AUTOSAR XML (schema 4-3-0)
package /MICROSAR/ComM_swc
  mode declaration group ComMMode: initial-mode=COMM_NO_COMMUNICATION
    mode COMM_NO_COMMUNICATION
    mode COMM_SILENT_COMMUNICATION
    mode COMM_FULL_COMMUNICATION
  data type mapping set ComMMode_DataTypeMappingSet: mode-request-type-map{implementation-data-type=ComM_ModeType, mode-group=ComMMode}  # Data Mapping for the Mode Declaration Group ComMMode.
package /MICROSAR/ComM_swc/DataTypes
  4 x impl type, all with category=TYPE_REFERENCE, implementation-data-type=uint8:
    ComM_ModeType: compu {0=COMM_NO_COMMUNICATION, 1=COMM_SILENT_COMMUNICATION, 2=COMM_FULL_COMMUNICATION}
    ComM_InhibitionStatusType: range raw 0..255
    ComM_UserHandleType: range raw 0..255
    NetworkHandleType: range raw 0..255, type-emitter=ComM
package /MICROSAR/ComM_swc/Interfaces
  4 x client server interface, all with is-service=true, service-kind=COM-MANAGER:
    ComM_UserRequest
      4 x operation:
        RequestComMode: possible-error=[ComM_UserRequest/E_NOT_OK, E_MODE_LIMITATION]
          arg ComMode: type=ComM_ModeType, direction=IN
        GetCurrentComMode: possible-error=ComM_UserRequest/E_NOT_OK
          arg ComMode: type=ComM_ModeType, direction=OUT
        GetMaxComMode: possible-error=ComM_UserRequest/E_NOT_OK
          arg ComMode: type=ComM_ModeType, direction=OUT
        GetRequestedComMode: possible-error=ComM_UserRequest/E_NOT_OK
          arg ComMode: type=ComM_ModeType, direction=OUT
      error E_NOT_OK: error-code=1
      error E_MODE_LIMITATION: error-code=2
    ComM_ECUModeLimitation
      4 x operation, all with possible-error=ComM_ECUModeLimitation/E_NOT_OK:
        LimitECUToNoComMode
          arg Status: type=boolean, direction=IN
        ReadInhibitCounter
          arg CounterValue: type=uint16, direction=OUT
        ResetInhibitCounter
        SetECUGroupClassification
          arg Status: type=ComM_InhibitionStatusType, direction=IN
      error E_NOT_OK: error-code=1
    ComM_ChannelWakeUp
      operation PreventWakeUp: possible-error=ComM_ChannelWakeUp/E_NOT_OK
        arg Status: type=boolean, direction=IN
      operation GetInhibitionStatus: possible-error=ComM_ChannelWakeUp/E_NOT_OK
        arg Status: type=ComM_InhibitionStatusType, direction=OUT
      error E_NOT_OK: error-code=1
    ComM_ChannelLimitation
      operation LimitChannelToNoComMode: possible-error=ComM_ChannelLimitation/E_NOT_OK
        arg Status: type=boolean, direction=IN
      operation GetInhibitionStatus: possible-error=ComM_ChannelLimitation/E_NOT_OK
        arg Status: type=ComM_InhibitionStatusType, direction=OUT
      error E_NOT_OK: error-code=1
  mode switch interface ComM_CurrentMode: is-service=true, service-kind=COM-MANAGER
    mode group currentMode: type=ComMMode
package /MICROSAR/ComM_swc/ComponentTypes
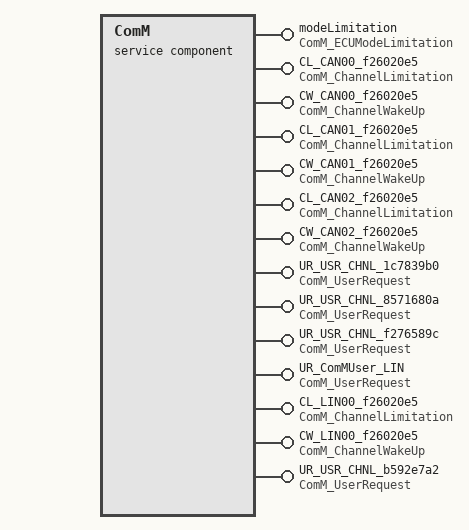
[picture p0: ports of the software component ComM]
  service sw component type ComM: category=SERVICE_COMPONENT
    14 x provide port:
      modeLimitation: provided-interface=ComM_ECUModeLimitation
      CL_CAN00_f26020e5: provided-interface=ComM_ChannelLimitation
      CW_CAN00_f26020e5: provided-interface=ComM_ChannelWakeUp
      CL_CAN01_f26020e5: provided-interface=ComM_ChannelLimitation
      CW_CAN01_f26020e5: provided-interface=ComM_ChannelWakeUp
      CL_CAN02_f26020e5: provided-interface=ComM_ChannelLimitation
      CW_CAN02_f26020e5: provided-interface=ComM_ChannelWakeUp
      UR_USR_CHNL_1c7839b0: provided-interface=ComM_UserRequest
      UR_USR_CHNL_8571680a: provided-interface=ComM_UserRequest
      UR_USR_CHNL_f276589c: provided-interface=ComM_UserRequest
      UR_ComMUser_LIN: provided-interface=ComM_UserRequest
      CL_LIN00_f26020e5: provided-interface=ComM_ChannelLimitation
      CW_LIN00_f26020e5: provided-interface=ComM_ChannelWakeUp
      UR_USR_CHNL_b592e7a2: provided-interface=ComM_UserRequest
    behavior ComMInternalBehavior: data-type-mapping=ComMMode_DataTypeMappingSet, handle-termination-and-restart=NO-SUPPORT, included-data-type-set=data-type=[ComM_ModeType, ComM_InhibitionStatusType, ComM_UserHandleType, NetworkHandleType]
      4 x timing event, all with period=0.02:
        Timer_ComM_MainFunction_{0..3}: start-on-event=ComM_MainFunction_{0..3}
      40 x operation invoked event:
        OpEventGetInhibitionStatus_GetInhibitionStatus_CL_CAN00_f26020e5: start-on-event=GetInhibitionStatus, operation=CL_CAN00_f26020e5.GetInhibitionStatus
        OpEventGetInhibitionStatus_GetInhibitionStatus_CW_CAN00_f26020e5: start-on-event=GetInhibitionStatus, operation=CW_CAN00_f26020e5.GetInhibitionStatus
        OpEventGetInhibitionStatus_GetInhibitionStatus_CL_CAN01_f26020e5: start-on-event=GetInhibitionStatus, operation=CL_CAN01_f26020e5.GetInhibitionStatus
        OpEventGetInhibitionStatus_GetInhibitionStatus_CW_CAN01_f26020e5: start-on-event=GetInhibitionStatus, operation=CW_CAN01_f26020e5.GetInhibitionStatus
        OpEventGetInhibitionStatus_GetInhibitionStatus_CL_CAN02_f26020e5: start-on-event=GetInhibitionStatus, operation=CL_CAN02_f26020e5.GetInhibitionStatus
        OpEventGetInhibitionStatus_GetInhibitionStatus_CW_CAN02_f26020e5: start-on-event=GetInhibitionStatus, operation=CW_CAN02_f26020e5.GetInhibitionStatus
        OpEventLimitECUToNoComMode_LimitECUToNoComMode_modeLimitation: start-on-event=LimitECUToNoComMode, operation=modeLimitation.LimitECUToNoComMode
        OpEventReadInhibitCounter_ReadInhibitCounter_modeLimitation: start-on-event=ReadInhibitCounter, operation=modeLimitation.ReadInhibitCounter
        OpEventResetInhibitCounter_ResetInhibitCounter_modeLimitation: start-on-event=ResetInhibitCounter, operation=modeLimitation.ResetInhibitCounter
        OpEventSetECUGroupClassification_SetECUGroupClassification_modeLimitation: start-on-event=SetECUGroupClassification, operation=modeLimitation.SetECUGroupClassification
        OpEventLimitChannelToNoComMode_LimitChannelToNoComMode_CL_CAN{00..02}_f26020e5: start-on-event=LimitChannelToNoComMode, operation=CL_CAN{00..02}_f26020e5.LimitChannelToNoComMode
        OpEventPreventWakeUp_PreventWakeUp_CW_CAN{00..02}_f26020e5: start-on-event=PreventWakeUp, operation=CW_CAN{00..02}_f26020e5.PreventWakeUp
        OpEventRequestComMode_RequestComMode_UR_USR_CHNL_1c7839b0: start-on-event=RequestComMode, operation=UR_USR_CHNL_1c7839b0.RequestComMode
        OpEventRequestComMode_RequestComMode_UR_USR_CHNL_8571680a: start-on-event=RequestComMode, operation=UR_USR_CHNL_8571680a.RequestComMode
        OpEventRequestComMode_RequestComMode_UR_USR_CHNL_f276589c: start-on-event=RequestComMode, operation=UR_USR_CHNL_f276589c.RequestComMode
        OpEventGetCurrentComMode_GetCurrentComMode_UR_USR_CHNL_1c7839b0: start-on-event=GetCurrentComMode, operation=UR_USR_CHNL_1c7839b0.GetCurrentComMode
        OpEventGetCurrentComMode_GetCurrentComMode_UR_USR_CHNL_8571680a: start-on-event=GetCurrentComMode, operation=UR_USR_CHNL_8571680a.GetCurrentComMode
        OpEventGetCurrentComMode_GetCurrentComMode_UR_USR_CHNL_f276589c: start-on-event=GetCurrentComMode, operation=UR_USR_CHNL_f276589c.GetCurrentComMode
        OpEventGetMaxComMode_GetMaxComMode_UR_USR_CHNL_1c7839b0: start-on-event=GetMaxComMode, operation=UR_USR_CHNL_1c7839b0.GetMaxComMode
        OpEventGetMaxComMode_GetMaxComMode_UR_USR_CHNL_8571680a: start-on-event=GetMaxComMode, operation=UR_USR_CHNL_8571680a.GetMaxComMode
        OpEventGetMaxComMode_GetMaxComMode_UR_USR_CHNL_f276589c: start-on-event=GetMaxComMode, operation=UR_USR_CHNL_f276589c.GetMaxComMode
        OpEventGetRequestedComMode_GetRequestedComMode_UR_USR_CHNL_1c7839b0: start-on-event=GetRequestedComMode, operation=UR_USR_CHNL_1c7839b0.GetRequestedComMode
        OpEventGetRequestedComMode_GetRequestedComMode_UR_USR_CHNL_8571680a: start-on-event=GetRequestedComMode, operation=UR_USR_CHNL_8571680a.GetRequestedComMode
        OpEventGetRequestedComMode_GetRequestedComMode_UR_USR_CHNL_f276589c: start-on-event=GetRequestedComMode, operation=UR_USR_CHNL_f276589c.GetRequestedComMode
        OpEventRequestComMode_RequestComMode_UR_ComMUser_LIN: start-on-event=RequestComMode, operation=UR_ComMUser_LIN.RequestComMode
        OpEventGetCurrentComMode_GetCurrentComMode_UR_ComMUser_LIN: start-on-event=GetCurrentComMode, operation=UR_ComMUser_LIN.GetCurrentComMode
        OpEventGetMaxComMode_GetMaxComMode_UR_ComMUser_LIN: start-on-event=GetMaxComMode, operation=UR_ComMUser_LIN.GetMaxComMode
        OpEventGetRequestedComMode_GetRequestedComMode_UR_ComMUser_LIN: start-on-event=GetRequestedComMode, operation=UR_ComMUser_LIN.GetRequestedComMode
        OpEventGetInhibitionStatus_GetInhibitionStatus_CL_LIN00_f26020e5: start-on-event=GetInhibitionStatus, operation=CL_LIN00_f26020e5.GetInhibitionStatus
        OpEventGetInhibitionStatus_GetInhibitionStatus_CW_LIN00_f26020e5: start-on-event=GetInhibitionStatus, operation=CW_LIN00_f26020e5.GetInhibitionStatus
        OpEventLimitChannelToNoComMode_LimitChannelToNoComMode_CL_LIN00_f26020e5: start-on-event=LimitChannelToNoComMode, operation=CL_LIN00_f26020e5.LimitChannelToNoComMode
        OpEventPreventWakeUp_PreventWakeUp_CW_LIN00_f26020e5: start-on-event=PreventWakeUp, operation=CW_LIN00_f26020e5.PreventWakeUp
        OpEventRequestComMode_RequestComMode_UR_USR_CHNL_b592e7a2: start-on-event=RequestComMode, operation=UR_USR_CHNL_b592e7a2.RequestComMode
        OpEventGetCurrentComMode_GetCurrentComMode_UR_USR_CHNL_b592e7a2: start-on-event=GetCurrentComMode, operation=UR_USR_CHNL_b592e7a2.GetCurrentComMode
        OpEventGetMaxComMode_GetMaxComMode_UR_USR_CHNL_b592e7a2: start-on-event=GetMaxComMode, operation=UR_USR_CHNL_b592e7a2.GetMaxComMode
        OpEventGetRequestedComMode_GetRequestedComMode_UR_USR_CHNL_b592e7a2: start-on-event=GetRequestedComMode, operation=UR_USR_CHNL_b592e7a2.GetRequestedComMode
      port-api-options:
        enable-take-address=true, indirect-api=false, port=modeLimitation
        {enable-take-address=true, indirect-api=false, port-defined-argument-value{value=0, value-type=NetworkHandleType}, port=CL_CAN00_f26020e5}
        {enable-take-address=true, indirect-api=false, port-defined-argument-value{value=0, value-type=NetworkHandleType}, port=CW_CAN00_f26020e5}
        {enable-take-address=true, indirect-api=false, port-defined-argument-value{value=1, value-type=NetworkHandleType}, port=CL_CAN01_f26020e5}
        {enable-take-address=true, indirect-api=false, port-defined-argument-value{value=1, value-type=NetworkHandleType}, port=CW_CAN01_f26020e5}
        {enable-take-address=true, indirect-api=false, port-defined-argument-value{value=2, value-type=NetworkHandleType}, port=CL_CAN02_f26020e5}
        {enable-take-address=true, indirect-api=false, port-defined-argument-value{value=2, value-type=NetworkHandleType}, port=CW_CAN02_f26020e5}
        {enable-take-address=true, indirect-api=false, port-defined-argument-value{value=2, value-type=ComM_UserHandleType}, port=UR_USR_CHNL_1c7839b0}
        {enable-take-address=true, indirect-api=false, port-defined-argument-value{value=1, value-type=ComM_UserHandleType}, port=UR_USR_CHNL_8571680a}
        {enable-take-address=true, indirect-api=false, port-defined-argument-value{value=0, value-type=ComM_UserHandleType}, port=UR_USR_CHNL_f276589c}
        {enable-take-address=true, indirect-api=false, port-defined-argument-value{value=3, value-type=ComM_UserHandleType}, port=UR_ComMUser_LIN}
        {enable-take-address=true, indirect-api=false, port-defined-argument-value{value=3, value-type=NetworkHandleType}, port=CL_LIN00_f26020e5}
        {enable-take-address=true, indirect-api=false, port-defined-argument-value{value=3, value-type=NetworkHandleType}, port=CW_LIN00_f26020e5}
        {enable-take-address=true, indirect-api=false, port-defined-argument-value{value=4, value-type=ComM_UserHandleType}, port=UR_USR_CHNL_b592e7a2}
      15 x runnable, all with can-be-invoked-concurrently=true:
        ComM_MainFunction_{0..3}
        GetInhibitionStatus: symbol=ComM_GetInhibitionStatus
        LimitECUToNoComMode: symbol=ComM_LimitECUToNoComMode
        ReadInhibitCounter: symbol=ComM_ReadInhibitCounter
        ResetInhibitCounter: symbol=ComM_ResetInhibitCounter
        SetECUGroupClassification: symbol=ComM_SetECUGroupClassification
        LimitChannelToNoComMode: symbol=ComM_LimitChannelToNoComMode
        PreventWakeUp: symbol=ComM_PreventWakeUp
        RequestComMode: symbol=ComM_RequestComMode
        GetCurrentComMode: symbol=ComM_GetCurrentComMode
        GetMaxComMode: symbol=ComM_GetMaxComMode
        GetRequestedComMode: symbol=ComM_GetRequestedComMode
  swc implementation ComMImplementation: programming-language=C, behavior=ComMInternalBehavior
